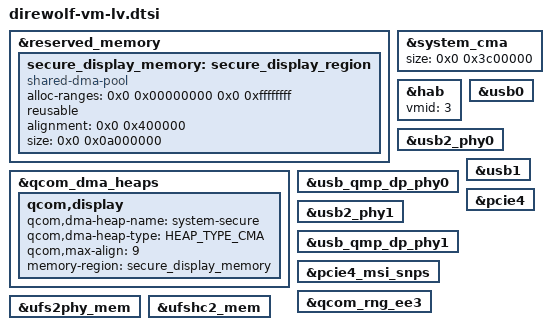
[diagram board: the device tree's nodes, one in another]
&reserved_memory {
	secure_display_memory: secure_display_region {
		compatible = "shared-dma-pool";
		alloc-ranges = <0x0 0x00000000 0x0 0xffffffff>;
		reusable;
		alignment = <0x0 0x400000>;
		size = <0x0 0x0a000000>;
	};
};

&qcom_dma_heaps {
	qcom,display {
		qcom,dma-heap-name = "system-secure";
		qcom,dma-heap-type = <HEAP_TYPE_CMA>;
		qcom,max-align = <9>;
		memory-region = <&secure_display_memory>;
	};
};

&system_cma {
	size = <0x0 0x3c00000>;
};

&hab {
	vmid = <3>;
};

&usb0 {
	status = "okay";
};

&usb2_phy0 {
	status = "okay";
};

&usb_qmp_dp_phy0 {
	status = "okay";
};

&usb1 {
	status = "okay";
};

&usb2_phy1 {
	status = "okay";
};

&usb_qmp_dp_phy1 {
	status = "okay";
};

&pcie4 {
	/delete-property/ iommu-map;
	status = "okay";
};

&pcie4_msi_snps {
	status = "okay";
};

&qcom_rng_ee3 {
	status = "okay";
};

&ufs2phy_mem {
	status = "ok";
};

&ufshc2_mem {
	status = "ok";
};
